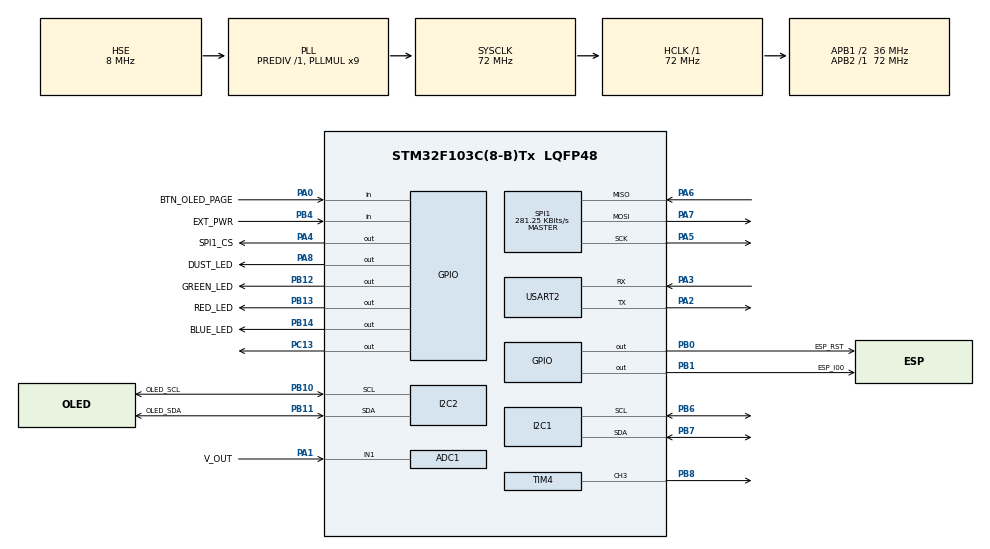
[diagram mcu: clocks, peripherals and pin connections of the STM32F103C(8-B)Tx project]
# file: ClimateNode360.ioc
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ADC1.Channel-0\#ChannelRegularConversion=ADC_CHANNEL_1
ADC1.NbrOfConversionFlag=1
ADC1.Rank-0\#ChannelRegularConversion=1
ADC1.SamplingTime-0\#ChannelRegularConversion=ADC_SAMPLETIME_28CYCLES_5
ADC1.master=1
Dma.ADC1.0.Direction=DMA_PERIPH_TO_MEMORY
Dma.ADC1.0.Instance=DMA1_Channel1
Dma.ADC1.0.MemDataAlignment=DMA_MDATAALIGN_HALFWORD
Dma.ADC1.0.MemInc=DMA_MINC_ENABLE
Dma.ADC1.0.Mode=DMA_NORMAL
Dma.ADC1.0.PeriphDataAlignment=DMA_PDATAALIGN_HALFWORD
Dma.ADC1.0.PeriphInc=DMA_PINC_DISABLE
Dma.ADC1.0.Priority=DMA_PRIORITY_LOW
Dma.I2C2_TX.1.Direction=DMA_MEMORY_TO_PERIPH
Dma.I2C2_TX.1.Instance=DMA1_Channel4
Dma.I2C2_TX.1.MemDataAlignment=DMA_MDATAALIGN_BYTE
Dma.I2C2_TX.1.MemInc=DMA_MINC_ENABLE
Dma.I2C2_TX.1.Mode=DMA_NORMAL
Dma.I2C2_TX.1.PeriphDataAlignment=DMA_PDATAALIGN_BYTE
Dma.I2C2_TX.1.PeriphInc=DMA_PINC_DISABLE
Dma.I2C2_TX.1.Priority=DMA_PRIORITY_LOW
Dma.Request0=ADC1
Dma.Request1=I2C2_TX
Dma.Request2=USART2_TX
Dma.USART2_TX.2.Direction=DMA_MEMORY_TO_PERIPH
Dma.USART2_TX.2.Instance=DMA1_Channel7
Dma.USART2_TX.2.MemDataAlignment=DMA_MDATAALIGN_BYTE
Dma.USART2_TX.2.MemInc=DMA_MINC_ENABLE
Dma.USART2_TX.2.Mode=DMA_NORMAL
Dma.USART2_TX.2.PeriphDataAlignment=DMA_PDATAALIGN_BYTE
Dma.USART2_TX.2.PeriphInc=DMA_PINC_DISABLE
Dma.USART2_TX.2.Priority=DMA_PRIORITY_LOW
I2C2.I2C_Mode=I2C_Standard
IWDG.Prescaler=IWDG_PRESCALER_256
Mcu.Family=STM32F1
Mcu.Name=STM32F103C(8-B)Tx
Mcu.Package=LQFP48
NVIC.DMA1_Channel1_IRQn=true\:0\:0\:false\:false\:true\:false\:true\:true
NVIC.DMA1_Channel4_IRQn=true\:0\:0\:false\:false\:true\:false\:true\:true
NVIC.DMA1_Channel7_IRQn=true\:0\:0\:false\:false\:true\:false\:true\:true
NVIC.I2C2_ER_IRQn=true\:0\:0\:false\:false\:true\:true\:true\:true
NVIC.I2C2_EV_IRQn=true\:0\:0\:false\:false\:true\:true\:true\:true
NVIC.PriorityGroup=NVIC_PRIORITYGROUP_4
NVIC.USART2_IRQn=true\:0\:0\:false\:false\:true\:false\:true\:true
PA0-WKUP.GPIO_Label=BTN_OLED_PAGE
PA0-WKUP.Signal=GPIO_Input
PA1.GPIO_Label=V_OUT
PA1.Signal=ADCx_IN1
PA13.Mode=Serial_Wire
PA13.Signal=SYS_JTMS-SWDIO
PA14.Mode=Serial_Wire
PA14.Signal=SYS_JTCK-SWCLK
PA2.Mode=Asynchronous
PA2.Signal=USART2_TX
PA3.Mode=Asynchronous
PA3.Signal=USART2_RX
PA4.GPIO_Label=SPI1_CS
PA4.PinState=GPIO_PIN_SET
PA4.Signal=GPIO_Output
PA5.Mode=Full_Duplex_Master
PA5.Signal=SPI1_SCK
PA6.GPIO_PuPd=GPIO_PULLUP
PA6.Mode=Full_Duplex_Master
PA6.Signal=SPI1_MISO
PA7.Mode=Full_Duplex_Master
PA7.Signal=SPI1_MOSI
PA8.GPIO_Label=DUST_LED
PA8.GPIO_ModeDefaultOutputPP=GPIO_MODE_OUTPUT_OD
PA8.GPIO_PuPd=GPIO_NOPULL
PA8.PinState=GPIO_PIN_SET
PA8.Signal=GPIO_Output
PB0.GPIO_Label=ESP_RST
PB0.GPIO_ModeDefaultOutputPP=GPIO_MODE_OUTPUT_PP
PB0.GPIO_PuPd=GPIO_NOPULL
PB0.PinState=GPIO_PIN_SET
PB0.Signal=GPIO_Output
PB1.GPIO_Label=ESP_I00
PB1.PinState=GPIO_PIN_SET
PB1.Signal=GPIO_Output
PB10.GPIO_Label=OLED_SCL
PB10.Mode=I2C
PB10.Signal=I2C2_SCL
PB11.GPIO_Label=OLED_SDA
PB11.Mode=I2C
PB11.Signal=I2C2_SDA
PB12.GPIO_Label=GREEN_LED
PB12.PinState=GPIO_PIN_SET
PB12.Signal=GPIO_Output
PB13.GPIO_Label=RED_LED
PB13.PinState=GPIO_PIN_SET
PB13.Signal=GPIO_Output
PB14.GPIO_Label=BLUE_LED
PB14.PinState=GPIO_PIN_SET
PB14.Signal=GPIO_Output
PB4.GPIO_Label=EXT_PWR
PB4.Signal=GPIO_Input
PB6.Mode=I2C
PB6.Signal=I2C1_SCL
PB7.Mode=I2C
PB7.Signal=I2C1_SDA
PB8.Signal=S_TIM4_CH3
PC13-TAMPER-RTC.Signal=GPIO_Output
PD0-OSC_IN.Mode=HSE-External-Oscillator
PD0-OSC_IN.Signal=RCC_OSC_IN
PD1-OSC_OUT.Mode=HSE-External-Oscillator
PD1-OSC_OUT.Signal=RCC_OSC_OUT
ProjectManager.HeapSize=0x200
ProjectManager.StackSize=0x400
ProjectManager.TargetToolchain=STM32CubeIDE
RCC.ADCPresc=RCC_ADCPCLK2_DIV6
RCC.AHBFreq_Value=72000000
RCC.APB1CLKDivider=RCC_HCLK_DIV2
RCC.APB1Freq_Value=36000000
RCC.APB1TimFreq_Value=72000000
RCC.APB2Freq_Value=72000000
RCC.APB2TimFreq_Value=72000000
RCC.HCLKFreq_Value=72000000
RCC.PLLMUL=RCC_PLL_MUL9
RCC.PLLSourceVirtual=RCC_PLLSOURCE_HSE
RCC.SYSCLKFreq_VALUE=72000000
RCC.SYSCLKSource=RCC_SYSCLKSOURCE_PLLCLK
RCC.USBFreq_Value=72000000
SH.ADCx_IN1.0=ADC1_IN1,IN1
SH.S_TIM4_CH3.0=TIM4_CH3,PWM Generation3 CH3
SPI1.BaudRatePrescaler=SPI_BAUDRATEPRESCALER_256
SPI1.CalculateBaudRate=281.25 KBits/s
SPI1.Direction=SPI_DIRECTION_2LINES
SPI1.Mode=SPI_MODE_MASTER
SPI1.VirtualType=VM_MASTER
TIM4.Channel-PWM\ Generation3\ CH3=TIM_CHANNEL_3
TIM4.Prescaler=71
USART2.VirtualMode=VM_ASYNC
VP_FATFS_VS_Generic.Mode=User_defined
VP_IWDG_VS_IWDG.Mode=IWDG_Activate
VP_TIM2_VS_ClockSourceINT.Mode=Internal
VP_TIM4_VS_ClockSourceINT.Mode=Internal
board=custom

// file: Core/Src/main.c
/* USER CODE BEGIN Header */
/**
  ******************************************************************************
  * @file           : main.c
  * @brief          : Main program body
  ******************************************************************************
  * @attention
  *
  * Copyright (c) 2026 STMicroelectronics.
  * All rights reserved.
  *
  * This software is licensed under terms that can be found in the LICENSE file
  * in the root directory of this software component.
  * If no LICENSE file comes with this software, it is provided AS-IS.
  *
  ******************************************************************************
  */
/* USER CODE END Header */
#include "main.h"
#include "fatfs.h"

/* USER CODE BEGIN Includes */
#include "general.h"
/* USER CODE END Includes */

ADC_HandleTypeDef hadc1;
DMA_HandleTypeDef hdma_adc1;

I2C_HandleTypeDef hi2c1;
I2C_HandleTypeDef hi2c2;
DMA_HandleTypeDef hdma_i2c2_tx;

IWDG_HandleTypeDef hiwdg;

SPI_HandleTypeDef hspi1;

TIM_HandleTypeDef htim2;
TIM_HandleTypeDef htim4;

UART_HandleTypeDef huart2;
DMA_HandleTypeDef hdma_usart2_tx;

void SystemClock_Config(void);
static void MX_GPIO_Init(void);
static void MX_DMA_Init(void);
static void MX_ADC1_Init(void);
static void MX_I2C1_Init(void);
static void MX_I2C2_Init(void);
static void MX_TIM2_Init(void);
static void MX_SPI1_Init(void);
static void MX_USART2_UART_Init(void);
static void MX_IWDG_Init(void);
static void MX_TIM4_Init(void);

int main(void)
{

  /* MCU Configuration--------------------------------------------------------*/

  /* Reset of all peripherals, Initializes the Flash interface and the Systick. */
  HAL_Init();

  /* Configure the system clock */
  SystemClock_Config();

  /* Initialize all configured peripherals */
  MX_GPIO_Init();
  MX_DMA_Init();
  MX_ADC1_Init();
  MX_I2C1_Init();
  MX_I2C2_Init();
  MX_TIM2_Init();
  MX_SPI1_Init();
  MX_USART2_UART_Init();
  MX_IWDG_Init();
  MX_FATFS_Init();
  MX_TIM4_Init();
  /* USER CODE BEGIN 2 */

  // Enable the Cortex-M3 DWT Cycle Counter
    CoreDebug->DEMCR |= CoreDebug_DEMCR_TRCENA_Msk;
    DWT->CYCCNT = 0;
    DWT->CTRL |= DWT_CTRL_CYCCNTENA_Msk;

  General_Init();
  /* USER CODE END 2 */

  /* Infinite loop */
  while (1)
  {

    /* USER CODE BEGIN 3 */
	  General_Run();
  }
  /* USER CODE END 3 */
}

void SystemClock_Config(void)
{
  RCC_OscInitTypeDef RCC_OscInitStruct = {0};
  RCC_ClkInitTypeDef RCC_ClkInitStruct = {0};
  RCC_PeriphCLKInitTypeDef PeriphClkInit = {0};

  /** Initializes the RCC Oscillators according to the specified parameters
  * in the RCC_OscInitTypeDef structure.
  */
  RCC_OscInitStruct.OscillatorType = RCC_OSCILLATORTYPE_LSI|RCC_OSCILLATORTYPE_HSE;
  RCC_OscInitStruct.HSEState = RCC_HSE_ON;
  RCC_OscInitStruct.HSEPredivValue = RCC_HSE_PREDIV_DIV1;
  RCC_OscInitStruct.HSIState = RCC_HSI_ON;
  RCC_OscInitStruct.LSIState = RCC_LSI_ON;
  RCC_OscInitStruct.PLL.PLLState = RCC_PLL_ON;
  RCC_OscInitStruct.PLL.PLLSource = RCC_PLLSOURCE_HSE;
  RCC_OscInitStruct.PLL.PLLMUL = RCC_PLL_MUL9;
  if (HAL_RCC_OscConfig(&RCC_OscInitStruct) != HAL_OK)
  {
    Error_Handler();
  }

  /** Initializes the CPU, AHB and APB buses clocks
  */
  RCC_ClkInitStruct.ClockType = RCC_CLOCKTYPE_HCLK|RCC_CLOCKTYPE_SYSCLK
                              |RCC_CLOCKTYPE_PCLK1|RCC_CLOCKTYPE_PCLK2;
  RCC_ClkInitStruct.SYSCLKSource = RCC_SYSCLKSOURCE_PLLCLK;
  RCC_ClkInitStruct.AHBCLKDivider = RCC_SYSCLK_DIV1;
  RCC_ClkInitStruct.APB1CLKDivider = RCC_HCLK_DIV2;
  RCC_ClkInitStruct.APB2CLKDivider = RCC_HCLK_DIV1;

  if (HAL_RCC_ClockConfig(&RCC_ClkInitStruct, FLASH_LATENCY_2) != HAL_OK)
  {
    Error_Handler();
  }
  PeriphClkInit.PeriphClockSelection = RCC_PERIPHCLK_ADC;
  PeriphClkInit.AdcClockSelection = RCC_ADCPCLK2_DIV6;
  if (HAL_RCCEx_PeriphCLKConfig(&PeriphClkInit) != HAL_OK)
  {
    Error_Handler();
  }
}

static void MX_ADC1_Init(void)
{

  ADC_ChannelConfTypeDef sConfig = {0};

  /** Common config
  */
  hadc1.Instance = ADC1;
  hadc1.Init.ScanConvMode = ADC_SCAN_DISABLE;
  hadc1.Init.ContinuousConvMode = DISABLE;
  hadc1.Init.DiscontinuousConvMode = DISABLE;
  hadc1.Init.ExternalTrigConv = ADC_SOFTWARE_START;
  hadc1.Init.DataAlign = ADC_DATAALIGN_RIGHT;
  hadc1.Init.NbrOfConversion = 1;
  if (HAL_ADC_Init(&hadc1) != HAL_OK)
  {
    Error_Handler();
  }

  /** Configure Regular Channel
  */
  sConfig.Channel = ADC_CHANNEL_1;
  sConfig.Rank = ADC_REGULAR_RANK_1;
  sConfig.SamplingTime = ADC_SAMPLETIME_28CYCLES_5;
  if (HAL_ADC_ConfigChannel(&hadc1, &sConfig) != HAL_OK)
  {
    Error_Handler();
  }

}

static void MX_I2C1_Init(void)
{

  hi2c1.Instance = I2C1;
  hi2c1.Init.ClockSpeed = 100000;
  hi2c1.Init.DutyCycle = I2C_DUTYCYCLE_2;
  hi2c1.Init.OwnAddress1 = 0;
  hi2c1.Init.AddressingMode = I2C_ADDRESSINGMODE_7BIT;
  hi2c1.Init.DualAddressMode = I2C_DUALADDRESS_DISABLE;
  hi2c1.Init.OwnAddress2 = 0;
  hi2c1.Init.GeneralCallMode = I2C_GENERALCALL_DISABLE;
  hi2c1.Init.NoStretchMode = I2C_NOSTRETCH_DISABLE;
  if (HAL_I2C_Init(&hi2c1) != HAL_OK)
  {
    Error_Handler();
  }

}

static void MX_I2C2_Init(void)
{

  hi2c2.Instance = I2C2;
  hi2c2.Init.ClockSpeed = 100000;
  hi2c2.Init.DutyCycle = I2C_DUTYCYCLE_2;
  hi2c2.Init.OwnAddress1 = 0;
  hi2c2.Init.AddressingMode = I2C_ADDRESSINGMODE_7BIT;
  hi2c2.Init.DualAddressMode = I2C_DUALADDRESS_DISABLE;
  hi2c2.Init.OwnAddress2 = 0;
  hi2c2.Init.GeneralCallMode = I2C_GENERALCALL_DISABLE;
  hi2c2.Init.NoStretchMode = I2C_NOSTRETCH_DISABLE;
  if (HAL_I2C_Init(&hi2c2) != HAL_OK)
  {
    Error_Handler();
  }

}

static void MX_IWDG_Init(void)
{

  hiwdg.Instance = IWDG;
  hiwdg.Init.Prescaler = IWDG_PRESCALER_256;
  hiwdg.Init.Reload = 4095;
  if (HAL_IWDG_Init(&hiwdg) != HAL_OK)
  {
    Error_Handler();
  }

}

static void MX_SPI1_Init(void)
{

  /* SPI1 parameter configuration*/
  hspi1.Instance = SPI1;
  hspi1.Init.Mode = SPI_MODE_MASTER;
  hspi1.Init.Direction = SPI_DIRECTION_2LINES;
  hspi1.Init.DataSize = SPI_DATASIZE_8BIT;
  hspi1.Init.CLKPolarity = SPI_POLARITY_LOW;
  hspi1.Init.CLKPhase = SPI_PHASE_1EDGE;
  hspi1.Init.NSS = SPI_NSS_SOFT;
  hspi1.Init.BaudRatePrescaler = SPI_BAUDRATEPRESCALER_256;
  hspi1.Init.FirstBit = SPI_FIRSTBIT_MSB;
  hspi1.Init.TIMode = SPI_TIMODE_DISABLE;
  hspi1.Init.CRCCalculation = SPI_CRCCALCULATION_DISABLE;
  hspi1.Init.CRCPolynomial = 10;
  if (HAL_SPI_Init(&hspi1) != HAL_OK)
  {
    Error_Handler();
  }

}

static void MX_TIM2_Init(void)
{

  TIM_ClockConfigTypeDef sClockSourceConfig = {0};
  TIM_MasterConfigTypeDef sMasterConfig = {0};

  htim2.Instance = TIM2;
  htim2.Init.Prescaler = 0;
  htim2.Init.CounterMode = TIM_COUNTERMODE_UP;
  htim2.Init.Period = 65535;
  htim2.Init.ClockDivision = TIM_CLOCKDIVISION_DIV1;
  htim2.Init.AutoReloadPreload = TIM_AUTORELOAD_PRELOAD_DISABLE;
  if (HAL_TIM_Base_Init(&htim2) != HAL_OK)
  {
    Error_Handler();
  }
  sClockSourceConfig.ClockSource = TIM_CLOCKSOURCE_INTERNAL;
  if (HAL_TIM_ConfigClockSource(&htim2, &sClockSourceConfig) != HAL_OK)
  {
    Error_Handler();
  }
  sMasterConfig.MasterOutputTrigger = TIM_TRGO_RESET;
  sMasterConfig.MasterSlaveMode = TIM_MASTERSLAVEMODE_DISABLE;
  if (HAL_TIMEx_MasterConfigSynchronization(&htim2, &sMasterConfig) != HAL_OK)
  {
    Error_Handler();
  }

}

static void MX_TIM4_Init(void)
{

  TIM_ClockConfigTypeDef sClockSourceConfig = {0};
  TIM_MasterConfigTypeDef sMasterConfig = {0};
  TIM_OC_InitTypeDef sConfigOC = {0};

  htim4.Instance = TIM4;
  htim4.Init.Prescaler = 71;
  htim4.Init.CounterMode = TIM_COUNTERMODE_UP;
  htim4.Init.Period = 65535;
  htim4.Init.ClockDivision = TIM_CLOCKDIVISION_DIV1;
  htim4.Init.AutoReloadPreload = TIM_AUTORELOAD_PRELOAD_DISABLE;
  if (HAL_TIM_Base_Init(&htim4) != HAL_OK)
  {
    Error_Handler();
  }
  sClockSourceConfig.ClockSource = TIM_CLOCKSOURCE_INTERNAL;
  if (HAL_TIM_ConfigClockSource(&htim4, &sClockSourceConfig) != HAL_OK)
  {
    Error_Handler();
  }
  if (HAL_TIM_PWM_Init(&htim4) != HAL_OK)
  {
    Error_Handler();
  }
  sMasterConfig.MasterOutputTrigger = TIM_TRGO_RESET;
  sMasterConfig.MasterSlaveMode = TIM_MASTERSLAVEMODE_DISABLE;
  if (HAL_TIMEx_MasterConfigSynchronization(&htim4, &sMasterConfig) != HAL_OK)
  {
    Error_Handler();
  }
  sConfigOC.OCMode = TIM_OCMODE_PWM1;
  sConfigOC.Pulse = 0;
  sConfigOC.OCPolarity = TIM_OCPOLARITY_HIGH;
  sConfigOC.OCFastMode = TIM_OCFAST_DISABLE;
  if (HAL_TIM_PWM_ConfigChannel(&htim4, &sConfigOC, TIM_CHANNEL_3) != HAL_OK)
  {
    Error_Handler();
  }
  HAL_TIM_MspPostInit(&htim4);

}

static void MX_USART2_UART_Init(void)
{

  huart2.Instance = USART2;
  huart2.Init.BaudRate = 115200;
  huart2.Init.WordLength = UART_WORDLENGTH_8B;
  huart2.Init.StopBits = UART_STOPBITS_1;
  huart2.Init.Parity = UART_PARITY_NONE;
  huart2.Init.Mode = UART_MODE_TX_RX;
  huart2.Init.HwFlowCtl = UART_HWCONTROL_NONE;
  huart2.Init.OverSampling = UART_OVERSAMPLING_16;
  if (HAL_UART_Init(&huart2) != HAL_OK)
  {
    Error_Handler();
  }

}

static void MX_DMA_Init(void)
{

  /* DMA controller clock enable */
  __HAL_RCC_DMA1_CLK_ENABLE();

  /* DMA interrupt init */
  /* DMA1_Channel1_IRQn interrupt configuration */
  HAL_NVIC_SetPriority(DMA1_Channel1_IRQn, 0, 0);
  HAL_NVIC_EnableIRQ(DMA1_Channel1_IRQn);
  /* DMA1_Channel4_IRQn interrupt configuration */
  HAL_NVIC_SetPriority(DMA1_Channel4_IRQn, 0, 0);
  HAL_NVIC_EnableIRQ(DMA1_Channel4_IRQn);
  /* DMA1_Channel7_IRQn interrupt configuration */
  HAL_NVIC_SetPriority(DMA1_Channel7_IRQn, 0, 0);
  HAL_NVIC_EnableIRQ(DMA1_Channel7_IRQn);

}

static void MX_GPIO_Init(void)
{
  GPIO_InitTypeDef GPIO_InitStruct = {0};

  /* GPIO Ports Clock Enable */
  __HAL_RCC_GPIOC_CLK_ENABLE();
  __HAL_RCC_GPIOD_CLK_ENABLE();
  __HAL_RCC_GPIOA_CLK_ENABLE();
  __HAL_RCC_GPIOB_CLK_ENABLE();

  /*Configure GPIO pin Output Level */
  HAL_GPIO_WritePin(GPIOC, GPIO_PIN_13, GPIO_PIN_RESET);

  /*Configure GPIO pin Output Level */
  HAL_GPIO_WritePin(GPIOA, SPI1_CS_Pin|DUST_LED_Pin, GPIO_PIN_SET);

  /*Configure GPIO pin Output Level */
  HAL_GPIO_WritePin(GPIOB, ESP_RST_Pin|ESP_I00_Pin|GREEN_LED_Pin|RED_LED_Pin
                          |BLUE_LED_Pin, GPIO_PIN_SET);

  /*Configure GPIO pin : PC13 */
  GPIO_InitStruct.Pin = GPIO_PIN_13;
  GPIO_InitStruct.Mode = GPIO_MODE_OUTPUT_PP;
  GPIO_InitStruct.Pull = GPIO_NOPULL;
  GPIO_InitStruct.Speed = GPIO_SPEED_FREQ_LOW;
  HAL_GPIO_Init(GPIOC, &GPIO_InitStruct);

  /*Configure GPIO pin : BTN_OLED_PAGE_Pin */
  GPIO_InitStruct.Pin = BTN_OLED_PAGE_Pin;
  GPIO_InitStruct.Mode = GPIO_MODE_INPUT;
  GPIO_InitStruct.Pull = GPIO_NOPULL;
  HAL_GPIO_Init(BTN_OLED_PAGE_GPIO_Port, &GPIO_InitStruct);

  /*Configure GPIO pin : SPI1_CS_Pin */
  GPIO_InitStruct.Pin = SPI1_CS_Pin;
  GPIO_InitStruct.Mode = GPIO_MODE_OUTPUT_PP;
  GPIO_InitStruct.Pull = GPIO_NOPULL;
  GPIO_InitStruct.Speed = GPIO_SPEED_FREQ_LOW;
  HAL_GPIO_Init(SPI1_CS_GPIO_Port, &GPIO_InitStruct);

  /*Configure GPIO pins : ESP_RST_Pin ESP_I00_Pin GREEN_LED_Pin RED_LED_Pin
                           BLUE_LED_Pin */
  GPIO_InitStruct.Pin = ESP_RST_Pin|ESP_I00_Pin|GREEN_LED_Pin|RED_LED_Pin
                          |BLUE_LED_Pin;
  GPIO_InitStruct.Mode = GPIO_MODE_OUTPUT_PP;
  GPIO_InitStruct.Pull = GPIO_NOPULL;
  GPIO_InitStruct.Speed = GPIO_SPEED_FREQ_LOW;
  HAL_GPIO_Init(GPIOB, &GPIO_InitStruct);

  /*Configure GPIO pin : DUST_LED_Pin */
  GPIO_InitStruct.Pin = DUST_LED_Pin;
  GPIO_InitStruct.Mode = GPIO_MODE_OUTPUT_OD;
  GPIO_InitStruct.Pull = GPIO_NOPULL;
  GPIO_InitStruct.Speed = GPIO_SPEED_FREQ_LOW;
  HAL_GPIO_Init(DUST_LED_GPIO_Port, &GPIO_InitStruct);

  /*Configure GPIO pin : EXT_PWR_Pin */
  GPIO_InitStruct.Pin = EXT_PWR_Pin;
  GPIO_InitStruct.Mode = GPIO_MODE_INPUT;
  GPIO_InitStruct.Pull = GPIO_NOPULL;
  HAL_GPIO_Init(EXT_PWR_GPIO_Port, &GPIO_InitStruct);

}

void Error_Handler(void)
{
  __disable_irq();
  while (1)
  {
  }
}
